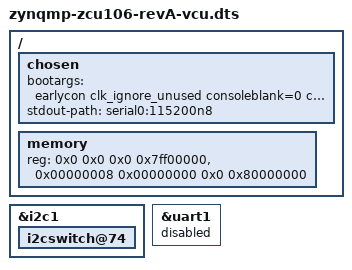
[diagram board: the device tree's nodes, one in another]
/*
 * dts file for Xilinx ZynqMP ZCU106 with VCU
 *
 * (C) Copyright 2018, Mentor Graphics, Inc.
 * (C) Copyright 2018, Xilinx, Inc.
 * 
 * Alexey Firago <alexey_firago@mentor.com>
 *
 * This program is free software; you can redistribute it and/or
 * modify it under the terms of the GNU General Public License as
 * published by the Free Software Foundation; either version 2 of
 * the License, or (at your option) any later version.
 */

#include "zynqmp-zcu106-revA.dts"
#include "vcu_trd/pcw.dtsi"


/* Define configuration */
#define CONFIG_TPG
#define CONFIG_CSI
#define CONFIG_HDMI_RX
#define CONFIG_HDMI_TX
#define CONFIG_VCU
#define CONFIG_APM

#include "vcu_trd/pl.dtsi"

/{
	chosen {
		bootargs = "earlycon clk_ignore_unused consoleblank=0 cma=1700M uio_pdrv_genirq.of_id=generic-uio";
		stdout-path = "serial0:115200n8";
	};

	memory {
		device_type = "memory";
		reg = <0x0 0x0 0x0 0x7ff00000>, <0x00000008 0x00000000 0x0 0x80000000>;
	};
};

&i2c1 {
	i2cswitch@74 {
	/delete-node/ 	i2c@2;
	};
};

&uart1 {
    status = "disabled";
};
